AUTOSAR XML (schema 00044)
package /E40_Platform_System_SystemPackage/Components
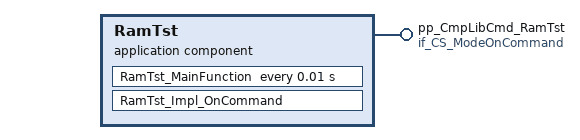
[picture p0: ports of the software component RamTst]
  application sw component type RamTst
    provide port pp_CmpLibCmd_RamTst: server-com-spec{operation=Impl_OnCommand, queue-length=1}, provided-interface=if_CS_ModeOnCommand
    behavior IB_RamTst: port-api-option{enable-take-address=false, indirect-api=false, port=pp_CmpLibCmd_RamTst}
      operation invoked event OIE_pp_CmpLibCmd_RamTst_RamTst_Impl_OnCommandTrigByImpl_OnCommand: start-on-event=RamTst_Impl_OnCommand, operation=pp_CmpLibCmd_RamTst.Impl_OnCommand
      timing event TERamTst_MainFunction: start-on-event=RamTst_MainFunction, period=0.01
      runnable RamTst_Impl_OnCommand: can-be-invoked-concurrently=true
      runnable RamTst_MainFunction: can-be-invoked-concurrently=true
  swc implementation IMPL_RamTst: behavior=IB_RamTst
